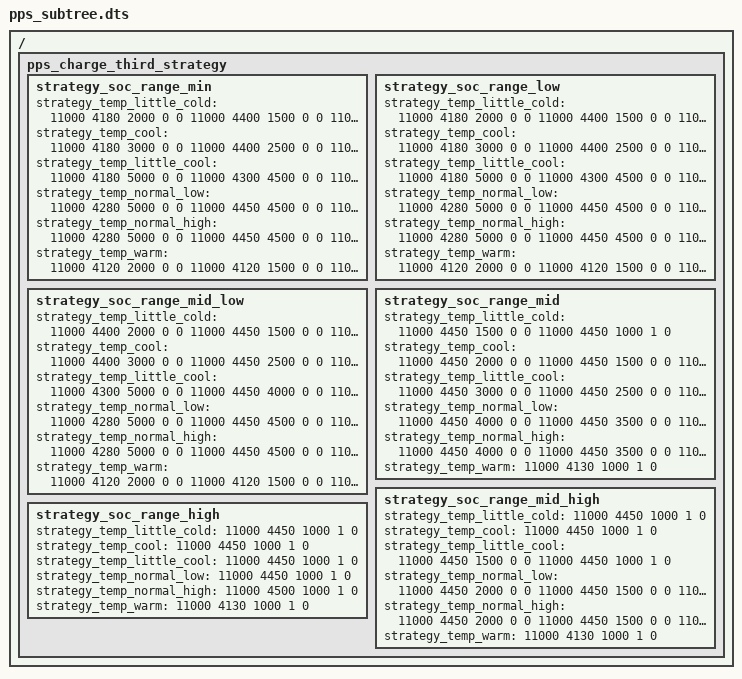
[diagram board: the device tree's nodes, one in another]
/dts-v1/;

/*
 * GENERATED by artifacts/dtbo/transcribe_audit.py from
 * artifacts/reports/pps_runtime_audit.md §9.2 -- verbatim, do not hand edit.
 *
 * v1 grammar (oplus_pps.c:212-228, :889-950): 6 soc children
 *   strategy_soc_range_{min,low,mid_low,mid,mid_high,high}, each with the 6
 *   strategy_temp_{little_cold,cool,little_cool,normal_low,normal_high,warm}
 *   arrays of <target_vbus target_vbat target_ibus exit target_time> 5-tuples.
 * Note: no oplus,soc_range / oplus,temp_range child properties -- v1 does not
 * parse them and audit §9.2 does not list them.
 */

/ {
pps_charge_third_strategy {
	strategy_soc_range_min {   /* soc   0 .. 15 */
		strategy_temp_little_cold = <11000 4180 2000 0 0  11000 4400 1500 0 0  11000 4450 1000 1 0>;
		strategy_temp_cool        = <11000 4180 3000 0 0  11000 4400 2500 0 0  11000 4450 1500 0 0  11000 4450 1000 1 0>;
		strategy_temp_little_cool = <11000 4180 5000 0 0  11000 4300 4500 0 0  11000 4450 4000 0 0  11000 4450 3500 0 0  11000 4450 3000 0 0  11000 4450 2000 0 0  11000 4500 1500 0 0  11000 4500 1000 1 0>;
		strategy_temp_normal_low  = <11000 4280 5000 0 0  11000 4450 4500 0 0  11000 4450 4000 0 0  11000 4450 3500 0 0  11000 4450 3000 0 0  11000 4450 2500 0 0  11000 4450 2000 0 0  11000 4500 1500 0 0  11000 4500 1000 1 0>;
		strategy_temp_normal_high = <11000 4280 5000 0 0  11000 4450 4500 0 0  11000 4450 4000 0 0  11000 4450 3500 0 0  11000 4450 3000 0 0  11000 4450 2500 0 0  11000 4450 2000 0 0  11000 4500 1500 0 0  11000 4500 1000 1 0>;
		strategy_temp_warm        = <11000 4120 2000 0 0  11000 4120 1500 0 0  11000 4130 1000 1 0>;
	};
	strategy_soc_range_low {   /* soc  15 .. 30 */
		strategy_temp_little_cold = <11000 4180 2000 0 0  11000 4400 1500 0 0  11000 4450 1000 1 0>;
		strategy_temp_cool        = <11000 4180 3000 0 0  11000 4400 2500 0 0  11000 4450 1500 0 0  11000 4450 1000 1 0>;
		strategy_temp_little_cool = <11000 4180 5000 0 0  11000 4300 4500 0 0  11000 4450 4000 0 0  11000 4450 3500 0 0  11000 4450 3000 0 0  11000 4450 2000 0 0  11000 4500 1000 1 0>;
		strategy_temp_normal_low  = <11000 4280 5000 0 0  11000 4450 4500 0 0  11000 4450 4000 0 0  11000 4450 3500 0 0  11000 4450 3000 0 0  11000 4450 2500 0 0  11000 4450 2000 0 0  11000 4500 1000 1 0>;
		strategy_temp_normal_high = <11000 4280 5000 0 0  11000 4450 4500 0 0  11000 4450 4000 0 0  11000 4450 3500 0 0  11000 4450 3000 0 0  11000 4450 2500 0 0  11000 4450 2000 0 0  11000 4500 1000 1 0>;
		strategy_temp_warm        = <11000 4120 2000 0 0  11000 4120 1500 0 0  11000 4130 1000 1 0>;
	};
	strategy_soc_range_mid_low { /* soc 30 .. 50 */
		strategy_temp_little_cold = <11000 4400 2000 0 0  11000 4450 1500 0 0  11000 4450 1000 1 0>;
		strategy_temp_cool        = <11000 4400 3000 0 0  11000 4450 2500 0 0  11000 4450 1500 0 0  11000 4450 1000 1 0>;
		strategy_temp_little_cool = <11000 4300 5000 0 0  11000 4450 4000 0 0  11000 4450 3500 0 0  11000 4450 3000 0 0  11000 4450 2500 0 0  11000 4450 2000 0 0  11000 4500 1000 1 0>;
		strategy_temp_normal_low  = <11000 4280 5000 0 0  11000 4450 4500 0 0  11000 4450 4000 0 0  11000 4450 3500 0 0  11000 4450 3000 0 0  11000 4450 2500 0 0  11000 4500 1000 1 0>;
		strategy_temp_normal_high = <11000 4280 5000 0 0  11000 4450 4500 0 0  11000 4450 4000 0 0  11000 4450 3500 0 0  11000 4450 3000 0 0  11000 4450 2500 0 0  11000 4500 1000 1 0>;
		strategy_temp_warm        = <11000 4120 2000 0 0  11000 4120 1500 0 0  11000 4130 1000 1 0>;
	};
	strategy_soc_range_mid {   /* soc  50 .. 75 */
		strategy_temp_little_cold = <11000 4450 1500 0 0  11000 4450 1000 1 0>;
		strategy_temp_cool        = <11000 4450 2000 0 0  11000 4450 1500 0 0  11000 4450 1000 1 0>;
		strategy_temp_little_cool = <11000 4450 3000 0 0  11000 4450 2500 0 0  11000 4450 2000 0 0  11000 4500 1500 0 0  11000 4500 1000 1 0>;
		strategy_temp_normal_low  = <11000 4450 4000 0 0  11000 4450 3500 0 0  11000 4450 3000 0 0  11000 4450 2500 0 0  11000 4450 2000 0 0  11000 4500 1500 0 0  11000 4500 1000 1 0>;
		strategy_temp_normal_high = <11000 4450 4000 0 0  11000 4450 3500 0 0  11000 4450 3000 0 0  11000 4450 2500 0 0  11000 4450 2000 0 0  11000 4500 1500 0 0  11000 4500 1000 1 0>;
		strategy_temp_warm        = <11000 4130 1000 1 0>;
	};
	strategy_soc_range_mid_high { /* soc 75 .. 85 */
		strategy_temp_little_cold = <11000 4450 1000 1 0>;
		strategy_temp_cool        = <11000 4450 1000 1 0>;
		strategy_temp_little_cool = <11000 4450 1500 0 0  11000 4450 1000 1 0>;
		strategy_temp_normal_low  = <11000 4450 2000 0 0  11000 4450 1500 0 0  11000 4500 1000 1 0>;
		strategy_temp_normal_high = <11000 4450 2000 0 0  11000 4450 1500 0 0  11000 4500 1000 1 0>;
		strategy_temp_warm        = <11000 4130 1000 1 0>;
	};
	strategy_soc_range_high {  /* soc  85 .. 90 */
		strategy_temp_little_cold = <11000 4450 1000 1 0>;
		strategy_temp_cool        = <11000 4450 1000 1 0>;
		strategy_temp_little_cool = <11000 4450 1000 1 0>;
		strategy_temp_normal_low  = <11000 4450 1000 1 0>;
		strategy_temp_normal_high = <11000 4500 1000 1 0>;
		strategy_temp_warm        = <11000 4130 1000 1 0>;
	};
};
};
